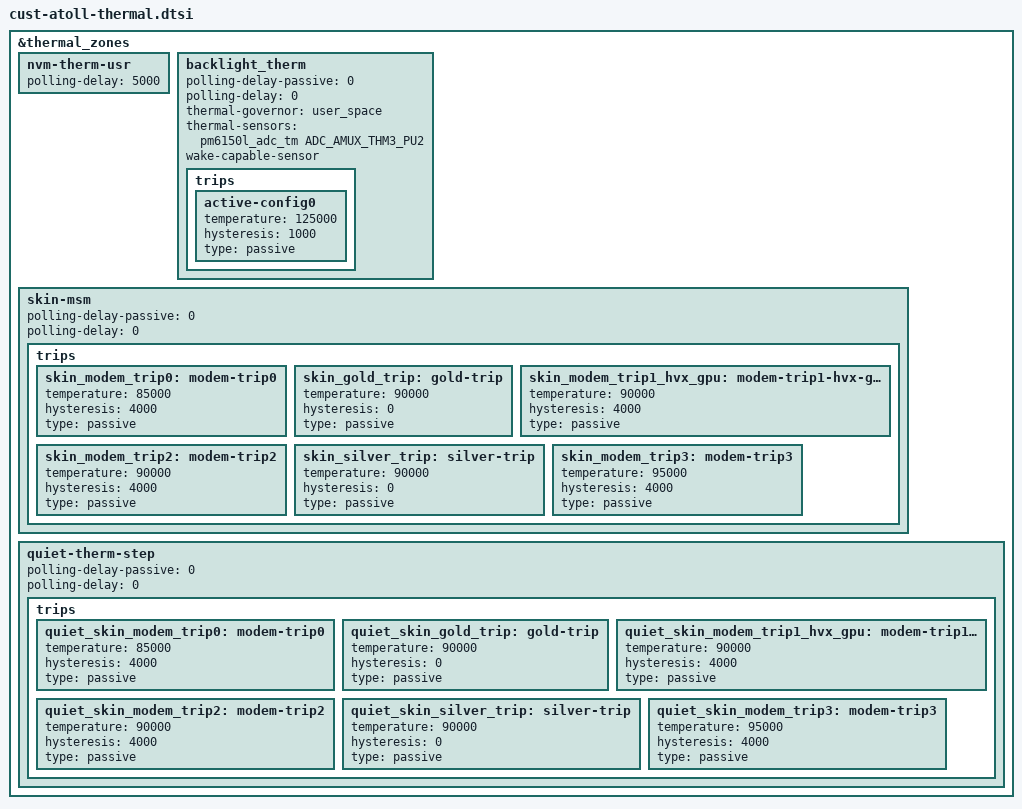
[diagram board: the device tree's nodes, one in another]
&thermal_zones {
	nvm-therm-usr {
		polling-delay = <5000>;
	};

	backlight_therm {
		polling-delay-passive = <0>;
		polling-delay = <0>;
		thermal-governor = "user_space";
		thermal-sensors = <&pm6150l_adc_tm ADC_AMUX_THM3_PU2>;
		wake-capable-sensor;
		trips {
			active-config0 {
				temperature = <125000>;
				hysteresis = <1000>;
				type = "passive";
			};
		};
	};

	skin-msm {
		polling-delay-passive = <0>;
		polling-delay = <0>;
		trips {
			skin_modem_trip0: modem-trip0 {
				temperature = <85000>;
				hysteresis = <4000>;
				type = "passive";
			};

			skin_gold_trip: gold-trip {
				temperature = <90000>;
				hysteresis = <0>;
				type = "passive";
			};

			skin_modem_trip1_hvx_gpu: modem-trip1-hvx-gpu {
				temperature = <90000>;
				hysteresis = <4000>;
				type = "passive";
			};

			skin_modem_trip2: modem-trip2 {
				temperature = <90000>;
				hysteresis = <4000>;
				type = "passive";
			};

			skin_silver_trip: silver-trip {
				temperature = <90000>;
				hysteresis = <0>;
				type = "passive";
			};

			skin_modem_trip3: modem-trip3 {
				temperature = <95000>;
				hysteresis = <4000>;
				type = "passive";
			};
		};
	};

	quiet-therm-step {
		polling-delay-passive = <0>;
		polling-delay = <0>;
		trips {
			quiet_skin_modem_trip0: modem-trip0 {
				temperature = <85000>;
				hysteresis = <4000>;
				type = "passive";
			};

			quiet_skin_gold_trip: gold-trip {
				temperature = <90000>;
				hysteresis = <0>;
				type = "passive";
			};

			quiet_skin_modem_trip1_hvx_gpu: modem-trip1-hvx-gpu {
				temperature = <90000>;
				hysteresis = <4000>;
				type = "passive";
			};

			quiet_skin_modem_trip2: modem-trip2 {
				temperature = <90000>;
				hysteresis = <4000>;
				type = "passive";
			};

			quiet_skin_silver_trip: silver-trip {
				temperature = <90000>;
				hysteresis = <0>;
				type = "passive";
			};

			quiet_skin_modem_trip3: modem-trip3 {
				temperature = <95000>;
				hysteresis = <4000>;
				type = "passive";
			};
		};
	};
};
